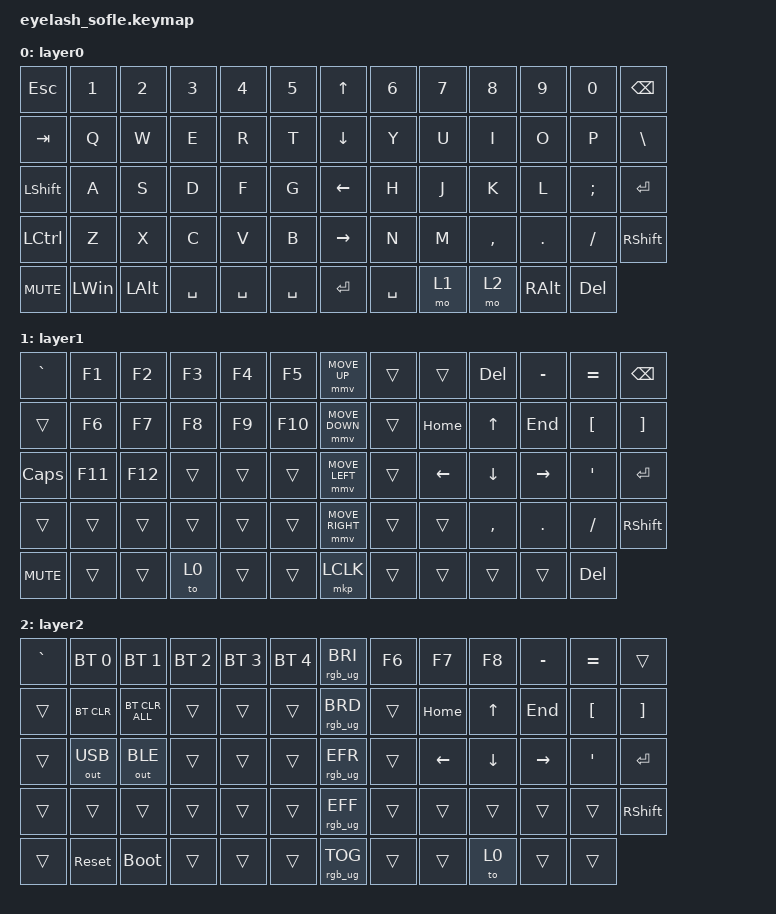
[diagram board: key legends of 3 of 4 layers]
#define ZMK_POINTING_DEFAULT_MOVE_VAL 1200  // 600
#define ZMK_POINTING_DEFAULT_SCRL_VAL 35    // 10

#include <input/processors.dtsi>
#include <zephyr/dt-bindings/input/input-event-codes.h>
#include <behaviors.dtsi>
#include <dt-bindings/zmk/bt.h>
#include <dt-bindings/zmk/keys.h>
#include <dt-bindings/zmk/outputs.h>
#include <dt-bindings/zmk/pointing.h>
#include <dt-bindings/zmk/rgb.h>

/ {
    zip_scroll_scaler: zip_scroll_scaler {
        compatible = "zmk,input-processor-scaler";
        #input-processor-cells = <2>;
        type = <INPUT_EV_REL>;
        codes = <INPUT_REL_WHEEL INPUT_REL_HWHEEL>;
        track-remainders;
    };
};

&mmv_input_listener { input-processors = <&zip_xy_scaler 2 1>; };

&msc_input_listener { input-processors = <&zip_scroll_scaler 2 1>; };

&msc {
    acceleration-exponent = <0>;      // 0
    time-to-max-speed-ms = <0>;       // 300
    delay-ms = <0>;                   // 0
};

&mmv {
    time-to-max-speed-ms = <400>;
    acceleration-exponent = <1>;
};

/ {
    scroll_encoder: scroll_encoder {
        compatible = "zmk,behavior-sensor-rotate";
        #sensor-binding-cells = <0>;
        bindings = <&msc SCRL_DOWN>, <&msc SCRL_UP>;

        tap-ms = <30>;
    };

    behaviors {
    };

    keymap {
        compatible = "zmk,keymap";

        layer0 {
            bindings = <
&kp ESC           &kp NUMBER_1  &kp N2        &kp N3     &kp N4     &kp N5       &kp UP_ARROW     &kp N6     &kp N7  &kp N8     &kp N9         &kp N0      &kp BACKSPACE
&kp TAB           &kp Q         &kp W         &kp E      &kp R      &kp T        &kp DOWN_ARROW   &kp Y      &kp U   &kp I      &kp O          &kp P       &kp BSLH
&kp LEFT_SHIFT    &kp A         &kp S         &kp D      &kp F      &kp G        &kp LEFT_ARROW   &kp H      &kp J   &kp K      &kp L          &kp SEMI    &kp ENTER
&kp LEFT_CONTROL  &kp Z         &kp X         &kp C      &kp V      &kp B        &kp RIGHT_ARROW  &kp N      &kp M   &kp COMMA  &kp DOT        &kp FSLH    &kp RIGHT_SHIFT
&kp C_MUTE        &kp LEFT_WIN  &kp LEFT_ALT  &kp SPACE  &kp SPACE  &kp SPACE    &kp ENTER        &kp SPACE  &mo 1   &mo 2      &kp RIGHT_ALT  &kp DELETE
            >;

            sensor-bindings = <&inc_dec_kp C_VOLUME_UP C_VOL_DN>;
            display-name = "layer0";
        };

        layer_1 {
            bindings = <
&kp GRAVE     &kp F1   &kp F2   &kp F3  &kp F4  &kp F5     &mmv MOVE_UP     &trans  &trans          &kp DEL         &kp MINUS  &kp EQUAL         &kp BACKSPACE
&trans        &kp F6   &kp F7   &kp F8  &kp F9  &kp F10    &mmv MOVE_DOWN   &trans  &kp HOME        &kp UP_ARROW    &kp END    &kp LEFT_BRACKET  &kp RIGHT_BRACKET
&kp CAPSLOCK  &kp F11  &kp F12  &trans  &trans  &trans     &mmv MOVE_LEFT   &trans  &kp LEFT_ARROW  &kp DOWN_ARROW  &kp RIGHT  &kp SINGLE_QUOTE  &kp ENTER
&trans        &trans   &trans   &trans  &trans  &trans     &mmv MOVE_RIGHT  &trans  &trans          &kp COMMA       &kp DOT    &kp SLASH         &kp RIGHT_SHIFT
&kp C_MUTE    &trans   &trans   &to 0   &trans  &trans     &mkp LCLK        &trans  &trans          &trans          &trans     &kp DEL
            >;

            display-name = "layer1";
            sensor-bindings = <&scroll_encoder>;
        };

        layer_2 {
            bindings = <
&kp GRAVE  &bt BT_SEL 0  &bt BT_SEL 1    &bt BT_SEL 2  &bt BT_SEL 3  &bt BT_SEL 4    &rgb_ug RGB_BRI  &kp F6  &kp F7          &kp F8          &kp MINUS  &kp EQUAL         &trans
&trans     &bt BT_CLR    &bt BT_CLR_ALL  &trans        &trans        &trans          &rgb_ug RGB_BRD  &trans  &kp HOME        &kp UP_ARROW    &kp END    &kp LEFT_BRACKET  &kp RIGHT_BRACKET
&trans     &out OUT_USB  &out OUT_BLE    &trans        &trans        &trans          &rgb_ug RGB_EFR  &trans  &kp LEFT_ARROW  &kp DOWN_ARROW  &kp RIGHT  &kp SINGLE_QUOTE  &kp ENTER
&trans     &trans        &trans          &trans        &trans        &trans          &rgb_ug RGB_EFF  &trans  &trans          &trans          &trans     &trans            &kp RIGHT_SHIFT
&trans     &sys_reset    &bootloader     &trans        &trans        &trans          &rgb_ug RGB_TOG  &trans  &trans          &to 0           &trans     &trans
            >;

            display-name = "layer2";
            sensor-bindings = <&scroll_encoder>;
        };

        layer_3 {
            bindings = <
&trans  &trans  &trans  &trans  &trans  &trans    &trans  &trans  &trans  &trans  &trans  &trans  &trans
&trans  &trans  &trans  &trans  &trans  &trans    &trans  &trans  &trans  &trans  &trans  &trans  &trans
&trans  &trans  &trans  &trans  &trans  &trans    &trans  &trans  &trans  &trans  &trans  &trans  &trans
&trans  &trans  &trans  &trans  &trans  &trans    &trans  &trans  &trans  &trans  &trans  &trans  &trans
&trans  &trans  &trans  &trans  &trans  &trans    &trans  &trans  &trans  &trans  &trans  &trans
&trans  &trans  &trans  &trans  &trans  &trans    &trans  &trans     &trans  &trans  &trans  &trans  &trans
&trans  &trans  &trans  &trans  &trans  &trans    &trans  &trans     &trans  &trans  &trans  &trans  &trans
&trans  &trans  &trans  &trans  &trans  &trans    &trans  &trans     &trans  &trans  &trans  &trans  &trans
&trans  &trans  &trans  &trans  &trans  &trans    &trans  &trans     &trans  &trans  &trans  &trans  &trans
&trans  &trans  &trans  &trans  &trans  &trans    &trans  &kp SPACE  &trans  &trans  &trans  &trans
            >;
        };
    };
};
